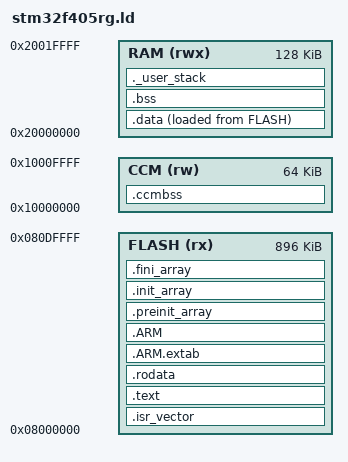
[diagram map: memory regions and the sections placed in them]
/* Linker script STM32F405RG: 1 MB flash, 128 KB SRAM, 64 KB CCM
 * The last flash sector (11, 128 KB @ 0x080E0000) is reserved for the
 * configuration and background data (flash_store.c). */
ENTRY(Reset_Handler)

_Min_Stack_Size = 0x2000;

MEMORY
{
  FLASH (rx)  : ORIGIN = 0x08000000, LENGTH = 896K
  RAM   (rwx) : ORIGIN = 0x20000000, LENGTH = 128K
  CCM   (rw)  : ORIGIN = 0x10000000, LENGTH = 64K
}

_estack = ORIGIN(RAM) + LENGTH(RAM);

SECTIONS
{
  .isr_vector : { . = ALIGN(4); KEEP(*(.isr_vector)) . = ALIGN(4); } > FLASH

  .text :
  {
    . = ALIGN(4);
    *(.text) *(.text*) *(.glue_7) *(.glue_7t) *(.eh_frame)
    KEEP(*(.init)) KEEP(*(.fini))
    . = ALIGN(4);
  } > FLASH

  .rodata : { . = ALIGN(4); *(.rodata) *(.rodata*) . = ALIGN(4); } > FLASH
  .ARM.extab : { *(.ARM.extab* .gnu.linkonce.armextab.*) } > FLASH
  .ARM : { __exidx_start = .; *(.ARM.exidx*) __exidx_end = .; } > FLASH

  .preinit_array : { PROVIDE_HIDDEN(__preinit_array_start = .); KEEP(*(.preinit_array*)) PROVIDE_HIDDEN(__preinit_array_end = .); } > FLASH
  .init_array : { PROVIDE_HIDDEN(__init_array_start = .); KEEP(*(SORT(.init_array.*))) KEEP(*(.init_array*)) PROVIDE_HIDDEN(__init_array_end = .); } > FLASH
  .fini_array : { PROVIDE_HIDDEN(__fini_array_start = .); KEEP(*(SORT(.fini_array.*))) KEEP(*(.fini_array*)) PROVIDE_HIDDEN(__fini_array_end = .); } > FLASH

  _sidata = LOADADDR(.data);
  .data :
  {
    . = ALIGN(4);
    _sdata = .;
    *(.data) *(.data*)
    . = ALIGN(4);
    _edata = .;
  } > RAM AT > FLASH

  .bss (NOLOAD) :
  {
    . = ALIGN(4);
    _sbss = .;
    __bss_start__ = _sbss;
    *(.bss) *(.bss*) *(COMMON)
    . = ALIGN(4);
    _ebss = .;
    __bss_end__ = _ebss;
  } > RAM

  /* DSP work buffers (not reachable by DMA - never put DMA buffers here) */
  .ccmbss (NOLOAD) :
  {
    . = ALIGN(4);
    _sccm = .;
    *(.ccmbss) *(.ccmbss*)
    . = ALIGN(4);
    _eccm = .;
  } > CCM

  ._user_stack (NOLOAD) :
  {
    . = ALIGN(8);
    PROVIDE(end = .);
    PROVIDE(_end = .);
    . = . + _Min_Stack_Size;
    . = ALIGN(8);
  } > RAM

  .ARM.attributes 0 : { *(.ARM.attributes) }
}
